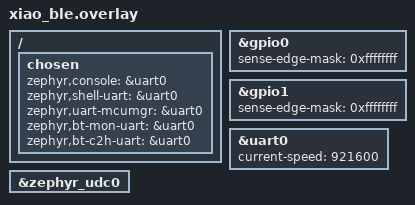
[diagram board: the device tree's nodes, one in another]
/ {
    chosen {
        zephyr,console = &uart0;
        zephyr,shell-uart = &uart0;
        zephyr,uart-mcumgr = &uart0;
        zephyr,bt-mon-uart = &uart0;
        zephyr,bt-c2h-uart = &uart0;
    };
};

&gpio0 {
    sense-edge-mask = < 0xffffffff >;
};

&gpio1 {
    sense-edge-mask = < 0xffffffff >;
};

&uart0 {
    current-speed = <921600>;
};

&zephyr_udc0 {
    /delete-node/ board_cdc_acm_uart;
};
